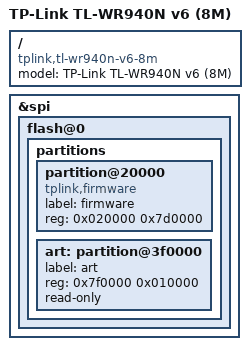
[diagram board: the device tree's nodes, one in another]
// SPDX-License-Identifier: GPL-2.0-or-later OR MIT
/dts-v1/;

#include "tp9343_tplink_tl-wr940n-v6-flashmod.dts"

/ {
	compatible = "tplink,tl-wr940n-v6-8m", "qca,tp9343";
	model = "TP-Link TL-WR940N v6 (8M)";
};

&spi {
	flash@0 {
		partitions {
			partition@20000 {
				compatible = "tplink,firmware";
				label = "firmware";
				reg = <0x020000 0x7d0000>;
			};

			art: partition@3f0000 {
				label = "art";
				reg = <0x7f0000 0x010000>;
				read-only;
			};
		};
	};
};
